# LPC18xx register map
File version: 18
Registers are 32-bit, read-write, reset 0x0 unless marked. A register's access mark holds for its fields unless they carry their own. Offsets are from the block's base; [hi:lo] are bit positions; {n}, {i} and the like mark numbered series; 'fields as' and 'values as' point back to an identical list.

## USB0 (part 1 of 2) — Product name title=UM10430 Chapter title=LPC18xx USB0 Host/Device/OTG controller Modification date=1/19/2011 Major revision=0 Minor revision=7
Base 0x40006000
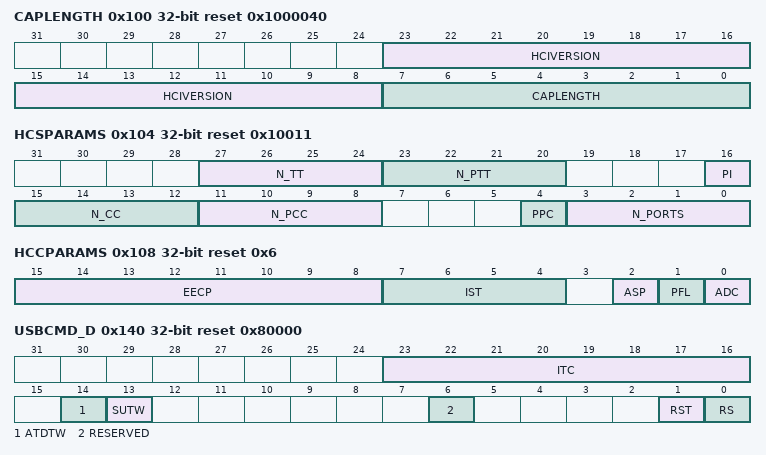
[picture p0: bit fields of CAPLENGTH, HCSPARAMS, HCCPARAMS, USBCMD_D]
0x100 CAPLENGTH ro reset 0x1000040 — Capability register length
  [23:8] HCIVERSION — BCD encoding of the EHCI revision number supported by this host controller.
  [7:0] CAPLENGTH — Indicates offset to add to the register base address at the beginning of the Operational Register
0x104 HCSPARAMS ro reset 0x10011 — Host controller structural parameters
  [27:24] N_TT — Number of Transaction Translators. This field indicates the number of embedded transaction translators associated with the USB2.0 host controller.
  [23:20] N_PTT — Number of Ports per Transaction Translator. This field indicates the number of ports assigned to each transaction translator within the USB2.0 host controller.
  [16] PI — Port indicators. This bit indicates whether the ports support port indicator control.
  [15:12] N_CC — Number of Companion Controller. This field indicates the number of companion controllers associated with this USB2.0 host controller.
  [11:8] N_PCC — Number of Ports per Companion Controller. This field indicates the number of ports supported per internal Companion Controller.
  [4] PPC — Port Power Control. This field indicates whether the host controller implementation includes port power control.
  [3:0] N_PORTS — Number of downstream ports. This field specifies the number of physical downstream ports implemented on this host controller.
0x108 HCCPARAMS ro reset 0x6 — Host controller capability parameters
  [15:8] EECP — EHCI Extended Capabilities Pointer. This optional field indicates the existence of a capabilities list.
  [7:4] IST — Isochronous Scheduling Threshold. This field indicates, relative to the current position of the executing host controller, where software can reliably update the isochronous schedule.
  [2] ASP — Asynchronous Schedule Park Capability. If this bit is set to a one, then the host controller supports the park feature for high-speed queue heads in the Asynchronous Schedule.The feature can be disabled or enabled and set to a specific level by using the Asynchronous Schedule Park Mode Enable and Asynchronous Schedule Park Mode Count fields in the USBCMD register.
  [1] PFL — Programmable Frame List Flag. If set to one, then the system software can specify and use a smaller frame list and configure the host controller via the USBCMD register Frame List Size field. The frame list must always be aligned on a 4K-boundary. This requirement ensures that the frame list is always physically contiguous.
  [0] ADC — 64-bit Addressing Capability. If zero, no 64-bit addressing capability is supported.
0x120 DCIVERSION ro reset 0x1 — Device interface version number
  [15:0] DCIVERSION — The device controller interface conforms to the two-byte BCD encoding of the interface version number contained in this register.
0x140 USBCMD_D reset 0x80000 — USB command (device mode)
  [23:16] ITC — Interrupt threshold control. The system software uses this field to set the maximum rate at which the host/device controller will issue interrupts. ITC contains the maximum interrupt interval measured in micro-frames. Valid values are shown below. All other values are reserved. 0x0 = Immediate (no threshold) 0x1 = 1 micro frame. 0x2 = 2 micro frames. 0x8 = 8 micro frames. 0x10 = 16 micro frames. 0x20 = 32 micro frames. 0x40 = 64 micro frames.
  [14] ATDTW — Add dTD trip wire This bit is used as a semaphore to ensure the to proper addition of a new dTD to an active (primed) endpoint's linked list. This bit is set and cleared by software during the process of adding a new dTD. See also Section 18.10. This bit shall also be cleared by hardware when its state machine is hazard region for which adding a dTD to a primed endpoint may go unrecognized.
  [13] SUTW — Setup trip wire During handling a setup packet, this bit is used as a semaphore to ensure that the setup data payload of 8 bytes is extracted from a QH by the DCD without being corrupted. If the setup lockout mode is off (see USBMODE register) then there exists a hazard when new setup data arrives while the DCD is copying the setup data payload from the QH for a previous setup packet. This bit is set and cleared by software and will be cleared by hardware when a hazard exists. (See Section 18.10).
  [6] RESERVED — Not used in device mode. Writing a one to this bit when the device mode is selected, will have undefined results.
  [1] RST — Controller reset. Software uses this bit to reset the controller. This bit is set to zero by the Host/Device Controller when the reset process is complete. Software cannot terminate the reset process early by writing a zero to this register.
    0=RESETCOMPLETE (Set to 0 by hardware when the reset process is complete.); 1=RESET (When software writes a one to this bit, the Device Controller resets its internal pipelines, timers, counters, state machines etc. to their initial values. Writing a one to this bit when the device is in the attached state is not recommended, since the effect on an attached host is undefined. In order to ensure that the device is not in an attached state before initiating a device controller reset, all primed endpoints should be flushed and the USBCMD Run/Stop bit should be set to 0.)
  [0] RS — Run/Stop
    0=DETACH (Writing a 0 to this bit will cause a detach event.); 1=ATTACH (Writing a one to this bit will cause the device controller to enable a pull-up on USB_DP and initiate an attach event. This control bit is not directly connected to the pull-up enable, as the pull-up will become disabled upon transitioning into high-speed mode. Software should use this bit to prevent an attach event before the device controller has been properly initialized.)
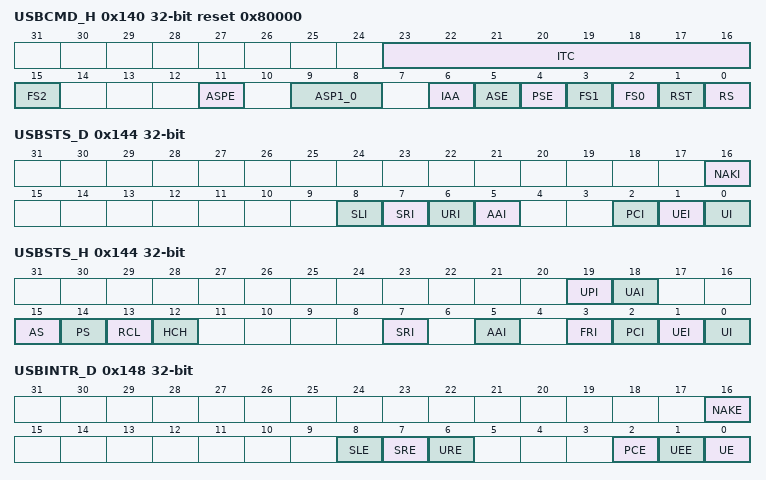
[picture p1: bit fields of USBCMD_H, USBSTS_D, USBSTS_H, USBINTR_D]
0x140 USBCMD_H reset 0x80000 (alternate view of USBCMD_D) — USB command (host mode)
  [23:16] ITC — Interrupt threshold control. The system software uses this field to set the maximum rate at which the host/device controller will issue interrupts. ITC contains the maximum interrupt interval measured in micro-frames. Valid values are shown below. All other values are reserved. 0x0 = Immediate (no threshold) 0x1 = 1 micro frame. 0x2 = 2 micro frames. 0x8 = 8 micro frames. 0x10 = 16 micro frames. 0x20 = 32 micro frames. 0x40 = 64 micro frames.
  [15] FS2 — Bit 2 of the Frame List Size bits. See Table 220.
  [11] ASPE — Asynchronous Schedule Park Mode Enable
    0=PARK_MODE_IS_DISABLE (Park mode is disabled.); 1=PARK_MODE_IS_ENABLED
  [9:8] ASP1_0 — Asynchronous schedule park mode Contains a count of the number of successive transactions the host controller is allowed to execute from a high-speed queue head on the Asynchronous schedule before continuing traversal of the Asynchronous schedule. Valid values are 0x1 to 0x3. Software must not write 00 to this bit when Park Mode Enable is one as this will result in undefined behavior.
  [6] IAA — This bit is used as a doorbell by software to tell the host controller to issue an interrupt the next time it advances asynchronous schedule.
    0=THE_HOST_CONTROLLER_ (The host controller sets this bit to zero after it has set the Interrupt on Sync Advance status bit in the USBSTS register to one.); 1=SOFTWARE_MUST_WRITE_ (Software must write a 1 to this bit to ring the doorbell. When the host controller has evicted all appropriate cached schedule states, it sets the Interrupt on Async Advance status bit in the USBSTS register. If the Interrupt on Sync Advance Enable bit in the USBINTR register is one, then the host controller will assert an interrupt at the next interrupt threshold. Software should not write a one to this bit when the asynchronous schedule is inactive. Doing so will yield undefined results.)
  [5] ASE — This bit controls whether the host controller skips processing the asynchronous schedule.
    0=DO_NOT_PROCESS_THE_A (Do not process the asynchronous schedule.); 1=USE_THE_ASYNCLISTADD (Use the ASYNCLISTADDR to access the asynchronous schedule.)
  [4] PSE — This bit controls whether the host controller skips processing the periodic schedule.
    0=DO_NOT_PROCESS_THE_P (Do not process the periodic schedule.); 1=USE_THE_PERIODICLIST (Use the PERIODICLISTBASE register to access the periodic schedule.)
  [3] FS1 — Bit 1 of the Frame List Size bits. See Table 220.
  [2] FS0 — Bit 0 of the Frame List Size bits. See Table 220. This field specifies the size of the frame list that controls which bits in the Frame Index Register should be used for the Frame List Current index. Note that this field is made up from USBCMD bits 15, 3, and 2.
  [1] RST — Controller reset. Software uses this bit to reset the controller. This bit is set to zero by the Host/Device Controller when the reset process is complete. Software cannot terminate the reset process early by writing a zero to this register.
    0=RESETCOMPLETE (This bit is set to zero by hardware when the reset process is complete.); 1=RESET (When software writes a one to this bit, the Host Controller resets its internal pipelines, timers, counters, state machines etc. to their initial value. Any transaction currently in progress on USB is immediately terminated. A USB reset is not driven on downstream ports. Software should not set this bit to a one when the HCHalted bit in the USBSTS register is a zero. Attempting to reset an actively running host controller will result in undefined behavior.)
  [0] RS — Run/Stop
    0=HALT (When this bit is set to 0, the Host Controller completes the current transaction on the USB and then halts. The HC Halted bit in the status register indicates when the Host Controller has finished the transaction and has entered the stopped state. Software should not write a one to this field unless the host controller is in the Halted state (i.e. HCHalted in the USBSTS register is a one).); 1=PROCEED (When set to a 1, the Host Controller proceeds with the execution of the schedule. The Host Controller continues execution as long as this bit is set to a one.)
0x144 USBSTS_D — USB status (device mode)
  [16] NAKI — NAK interrupt bit
    0=ST (This bit is automatically cleared by hardware when the all the enabled TX/RX Endpoint NAK bits are cleared.); 1=CLEAR (It is set by hardware when for a particular endpoint both the TX/RX Endpoint NAK bit and the corresponding TX/RX Endpoint NAK Enable bit are set.)
  [8] SLI — DCSuspend
    0=ST (The device controller clears the bit upon exiting from a suspend state. This bit is cleared by software writing a one to it.); 1=CLEAR (When a device controller enters a suspend state from an active state, this bit will be set to a one.)
  [7] SRI — SOF received
    0=ST (This bit is cleared by software writing a one to it.); 1=CLEAR (When the device controller detects a Start Of (micro) Frame, this bit will be set to a one. When a SOF is extremely late, the device controller will automatically set this bit to indicate that an SOF was expected. Therefore, this bit will be set roughly every 1 ms in device FS mode and every 125 ms in HS mode and will be synchronized to the actual SOF that is received. Since the device controller is initialized to FS before connect, this bit will be set at an interval of 1ms during the prelude to connect and chirp.)
  [6] URI — USB reset received
    0=ST (This bit is cleared by software writing a one to it.); 1=CLEAR (When the device controller detects a USB Reset and enters the default state, this bit will be set to a one.)
  [5] AAI — Not used in Device mode.
  [2] PCI — Port change detect.
    0=ST (This bit is cleared by software writing a one to it.); 1=CLEAR (The Device Controller sets this bit to a one when the port controller enters the full or high-speed operational state. When the port controller exits the full or high-speed operation states due to Reset or Suspend events, the notification mechanisms are the USB Reset Received bit (URI) and the DCSuspend bits (SLI) respectively.)
  [1] UEI — USB error interrupt
    0=ST (This bit is cleared by software writing a one to it.); 1=CLEAR (When completion of a USB transaction results in an error condition, this bit is set by the Host/Device Controller. This bit is set along with the USBINT bit, if the TD on which the error interrupt occurred also had its interrupt on complete (IOC) bit set. The device controller detects resume signaling only (see Section 18.10.11.6).)
  [0] UI — USB interrupt
    0=ST (This bit is cleared by software writing a one to it.); 1=CLEAR (This bit is set by the Host/Device Controller when the cause of an interrupt is a completion of a USB transaction where the Transfer Descriptor (TD) has an interrupt on complete (IOC) bit set. This bit is also set by the Host/Device Controller when a short packet is detected. A short packet is when the actual number of bytes received was less than the expected number of bytes.)
0x144 USBSTS_H (alternate view of USBSTS_D) — USB status (host mode)
  [19] UPI — USB host periodic interrupt (USBHSTPERINT)
    0=ST (This bit is cleared by software writing a one to it.); 1=CLEAR (This bit is set by the Host Controller when the cause of an interrupt is a completion of a USB transaction where the Transfer Descriptor (TD) has an interrupt on complete (IOC) bit set and the TD was from the periodic schedule. This bit is also set by the Host Controller when a short packet is detected and the packet is on the periodic schedule. A short packet is when the actual number of bytes received was less than the expected number of bytes.)
  [18] UAI — USB host asynchronous interrupt (USBHSTASYNCINT)
    0=ST (This bit is cleared by software writing a one to it.); 1=CLEAR (This bit is set by the Host Controller when the cause of an interrupt is a completion of a USB transaction where the Transfer Descriptor (TD) has an interrupt on complete (IOC) bit set and the TD was from the asynchronous schedule. This bit is also set by the Host when a short packet is detected and the packet is on the asynchronous schedule. A short packet is when the actual number of bytes received was less than the expected number of bytes.)
  [15] AS — Asynchronous schedule status This bit reports the current real status of the Asynchronous Schedule. The Host Controller is not required to immediately disable or enable the Asynchronous Schedule when software transitions the Asynchronous Schedule Enable bit in the USBCMD register. When this bit and the Asynchronous Schedule Enable bit are the same value, the Asynchronous Schedule is either enabled (if both are 1) or disabled (if both are 0).
    0=DISABLED (Asynchronous schedule status is disabled.); 1=DISABLED (Asynchronous schedule status is enabled.)
  [14] PS — Periodic schedule status This bit reports the current real status of the Periodic Schedule. The Host Controller is not required to immediately disable or enable the Periodic Schedule when software transitions the Periodic Schedule Enable bit in the USBCMD register. When this bit and the Periodic Schedule Enable bit are the same value, the Periodic Schedule is either enabled (if both are 1) or disabled (if both are 0).
    0=DISABLED (The periodic schedule status is disabled.); 1=DISABLED (The periodic schedule status is enabled.)
  [13] RCL — Reclamation
    0=NO_EMPTY_ASYNCHRONOU (No empty asynchronous schedule detected.); 1=EMPTY_ASYNCHRONOU (An empty asynchronous schedule is detected. Set by the host controller.)
  [12] HCH — HCHalted
    0=RS (The RS bit in USBCMD is set to zero. Set by the host controller.); 1=HALT (The Host Controller sets this bit to one after it has stopped executing because of the Run/Stop bit being set to 0, either by software or by the Host Controller hardware (e.g. because of an internal error).)
  [7] SRI — SOF received
    0=ST (This bit is cleared by software writing a one to it.); 1=CLEAR (In host mode, this bit will be set every 125 ms and can be used by host controller driver as a time base.)
  [5] AAI — Interrupt on async advance
    0=ST (This bit is cleared by software writing a one to it.); 1=CLEAR (System software can force the host controller to issue an interrupt the next time the host controller advances the asynchronous schedule by writing a one to the Interrupt on Async Advance Doorbell bit in the USBCMD register. This status bit indicates the assertion of that interrupt source.)
  [3] FRI — Frame list roll-over
    0=ST (This bit is cleared by software writing a one to it.); 1=CLEAR (The Host Controller sets this bit to a one when the Frame List Index rolls over from its maximum value to zero. The exact value at which the rollover occurs depends on the frame list size. For example, if the frame list size (as programmed in the Frame List Size field of the USBCMD register) is 1024, the Frame Index Register rolls over every time FRINDEX bit 13 toggles. Similarly, if the size is 512, the Host Controller sets this bit to a one every time FRINDEX bit 12 toggles (see Section 18.6.6).)
  [2] PCI — Port change detect.
    0=ST (This bit is cleared by software writing a one to it.); 1=CLEAR (The Host Controller sets this bit to a one when on any port a Connect Status occurs, a Port Enable/Disable Change occurs, or the Force Port Resume bit is set as the result of a J-K transition on the suspended port.)
  [1] UEI — USB error interrupt (USBERRINT)
    0=ST (This bit is cleared by software writing a one to it.); 1=CLEAR (When completion of a USB transaction results in an error condition, this bit is set by the Host/Device Controller. This bit is set along with the USBINT bit, if the TD on which the error interrupt occurred also had its interrupt on complete (IOC) bit set.)
  [0] UI — USB interrupt (USBINT)
    values as USBSTS_D.UI
0x148 USBINTR_D — USB interrupt enable (device mode)
  [16] NAKE — NAK interrupt enable This bit is set by software if it wants to enable the hardware interrupt for the NAK Interrupt bit. If both this bit and the corresponding NAK Interrupt bit are set, a hardware interrupt is generated.
  [8] SLE — Sleep enable When this bit is a one, and the DCSuspend bit in the USBSTS register transitions, the device controller will issue an interrupt. The interrupt is acknowledged by software writing a one to the DCSuspend bit.
  [7] SRE — SOF received enable When this bit is a one, and the SOF Received bit in the USBSTS register is a one, the device controller will issue an interrupt. The interrupt is acknowledged by software clearing the SOF Received bit.
  [6] URE — USB reset enable When this bit is a one, and the USB Reset Received bit in the USBSTS register is a one, the device controller will issue an interrupt. The interrupt is acknowledged by software clearing the USB Reset Received bit.
  [2] PCE — Port change detect enable When this bit is a one, and the Port Change Detect bit in the USBSTS register is a one, the host/device controller will issue an interrupt. The interrupt is acknowledged by software clearing the Port Change Detect bit in USBSTS.
  [1] UEE — USB error interrupt enable When this bit is a one, and the USBERRINT bit in the USBSTS register is a one, the host/device controller will issue an interrupt at the next interrupt threshold. The interrupt is acknowledged by software clearing the USBERRINT bit in the USBSTS register.
  [0] UE — USB interrupt enable When this bit is one, and the USBINT bit in the USBSTS register is one, the host/device controller will issue an interrupt at the next interrupt threshold. The interrupt is acknowledged by software clearing the USBINT bit in USBSTS.
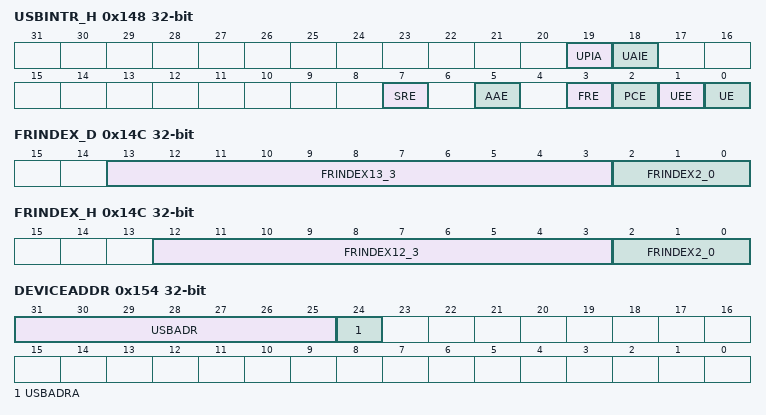
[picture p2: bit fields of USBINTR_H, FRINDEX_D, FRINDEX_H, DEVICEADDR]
0x148 USBINTR_H (alternate view of USBINTR_D) — USB interrupt enable (host mode)
  [19] UPIA — USB host periodic interrupt enable When this bit is a one, and the USBHSTPERINT bit in the USBSTS register is a one, the host controller will issue an interrupt at the next interrupt threshold. The interrupt is acknowledged by software clearing the USBHSTPERINT bit.
  [18] UAIE — USB host asynchronous interrupt enable When this bit is a one, and the USBHSTASYNCINT bit in the USBSTS register is a one, the host controller will issue an interrupt at the next interrupt threshold. The interrupt is acknowledged by software clearing the USBHSTASYNCINT bit.
  [7] SRE — If this bit is one and the SRI bit in the USBSTS register is one, the host controller will issue an interrupt. In host mode, the SRI bit will be set every 125 ms and can be used by the host controller as a time base. The interrupt is acknowledged by software clearing the SRI bit in the USBSTS register.
  [5] AAE — Interrupt on asynchronous advance enable When this bit is a one, and the Interrupt on Async Advance bit in the USBSTS register is a one, the host controller will issue an interrupt at the next interrupt threshold. The interrupt is acknowledged by software clearing the Interrupt on Async Advance bit.
  [3] FRE — Frame list rollover enable When this bit is a one, and the Frame List Rollover bit in the USBSTS register is a one, the host controller will issue an interrupt. The interrupt is acknowledged by software clearing the Frame List Rollover bit.
  [2] PCE — Port change detect enable When this bit is a one, and the Port Change Detect bit in the USBSTS register is a one, the host/device controller will issue an interrupt. The interrupt is acknowledged by software clearing the Port Change Detect bit in USBSTS.
  [1] UEE — USB error interrupt enable When this bit is a one, and the USBERRINT bit in the USBSTS register is a one, the host/device controller will issue an interrupt at the next interrupt threshold. The interrupt is acknowledged by software clearing the USBERRINT bit in the USBSTS register.
  [0] UE — USB interrupt enable When this bit is one, and the USBINT bit in the USBSTS register is one, the host/device controller will issue an interrupt at the next interrupt threshold. The interrupt is acknowledged by software clearing the USBINT bit in USBSTS.
0x14C FRINDEX_D — USB frame index (device mode)
  [13:3] FRINDEX13_3 — Current frame number of the last frame transmitted
  [2:0] FRINDEX2_0 — Current micro frame number
0x14C FRINDEX_H (alternate view of FRINDEX_D) — USB frame index (host mode)
  [12:3] FRINDEX12_3 — Frame list current index.
  [2:0] FRINDEX2_0 — Current micro frame number
0x154 DEVICEADDR — USB device address (device mode)
  [31:25] USBADR — USB device address
  [24] USBADRA — Device address advance
    0=INSTANTANEOUS (Any write to USBADR are instantaneous.); 1=DELAYED (When the user writes a one to this bit at the same time or before USBADR is written, the write to USBADR fields is staged and held in a hidden register. After an IN occurs on endpoint 0 and is acknowledged, USBADR will be loaded from the holding register. Hardware will automatically clear this bit on the following conditions: IN is ACKed to endpoint 0. USBADR is updated from the staging register. OUT/SETUP occurs on endpoint 0. USBADR is not updated. Device reset occurs. USBADR is set to 0. After the status phase of the SET_ADDRESS descriptor, the DCD has 2 ms to program the USBADR field. This mechanism will ensure this specification is met when the DCD can not write the device address within 2 ms from the SET_ADDRESS status phase. If the DCD writes the USBADR with USBADRA=1 after the SET_ADDRESS data phase (before the prime of the status phase), the USBADR will be programmed instantly at the correct time and meet the 2 ms USB requirement.)
0x154 PERIODICLISTBASE (alternate view of DEVICEADDR) — Frame list base address (host mode)
  [31:12] PERBASE31_12 — Base Address (Low) These bits correspond to the memory address signals 31:12.
0x158 ENDPOINTLISTADDR — Address of endpoint list in memory
  [31:11] EPBASE31_11 — Endpoint list pointer (low) These bits correspond to memory address signals 31:11, respectively. This field will reference a list of up to 4 Queue Heads (QH). (i.e. one queue head per endpoint and direction.)
0x158 ASYNCLISTADDR (alternate view of ENDPOINTLISTADDR) — Address of endpoint list in memory
  [31:5] ASYBASE31_5 — Link pointer (Low) LPL These bits correspond to memory address signals 31:5, respectively. This field may only reference a Queue Head (OH).
0x15C TTCTRL — Asynchronous buffer status for embedded TT (host mode)
  [30:24] TTHA — Hub address when FS or LS device are connected directly.
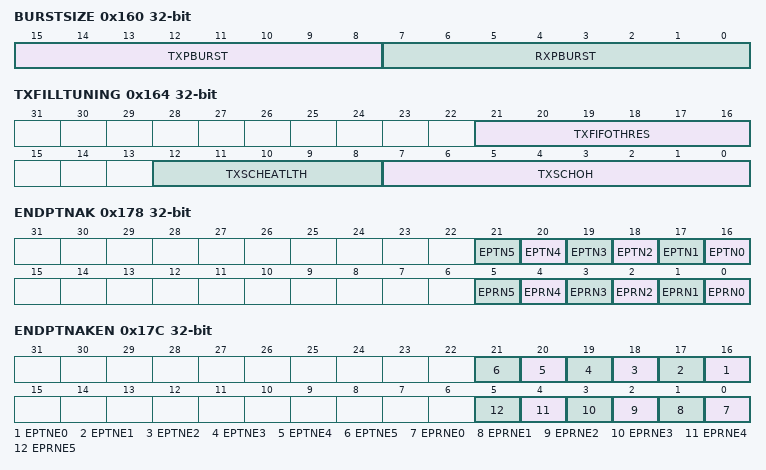
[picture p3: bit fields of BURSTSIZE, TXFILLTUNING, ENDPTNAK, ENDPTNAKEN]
0x160 BURSTSIZE — Programmable burst size
  [15:8] TXPBURST — Programmable TX burst length This register represents the maximum length of a burst in 32-bit words while moving data from system memory to the USB bus.
  [7:0] RXPBURST — Programmable RX burst length This register represents the maximum length of a burst in 32-bit words while moving data from the USB bus to system memory.
0x164 TXFILLTUNING — Host transmit pre-buffer packet tuning (host mode)
  [21:16] TXFIFOTHRES — Scheduler overhead This register adds an additional fixed offset to the schedule time estimator described above as Tff. As an approximation, the value chosen for this register should limit the number of back-off events captured in the TXSCHHEALTH to less than 10 per second in a highly utilized bus. Choosing a value that is too high for this register is not desired as it can needlessly reduce USB utilization. The time unit represented in this register is 1.267 ms when a device is connected in High-Speed Mode for OTG and SPH. The time unit represented in this register is 6.333 ms when a device is connected in Low/Full Speed Mode for OTG and SPH.
  [12:8] TXSCHEATLTH — Scheduler health counter This register increments when the host controller fails to fill the TX latency FIFO to the level programmed by TXFIFOTHRES before running out of time to send the packet before the next Start-Of-Frame . This health counter measures the number of times this occurs to provide feedback to selecting a proper TXSCHOH. Writing to this register will clear the counter. The maximum value is 31.
  [7:0] TXSCHOH — FIFO burst threshold This register controls the number of data bursts that are posted to the TX latency FIFO in host mode before the packet begins on to the bus. The minimum value is 2 and this value should be a low as possible to maximize USB performance. A higher value can be used in systems with unpredictable latency and/or insufficient bandwidth where the FIFO may underrun because the data transferred from the latency FIFO to USB occurs before it can be replenished from system memory. This value is ignored if the Stream Disable bit in USBMODE register is set.
0x174 BINTERVAL — Length of virtual frame
  [3:0] BINT — bInterval value (see Section 18.7.7)
0x178 ENDPTNAK — Endpoint NAK (device mode)
  [n+16] EPTN{n} (n=0..5) — Tx endpoint NAK Each TX endpoint has one bit in this field. The bit is set when the device sends a NAK handshake on a received IN token for the corresponding endpoint. Bit 3 corresponds to endpoint 3. ... Bit 1 corresponds to endpoint 1. Bit 0 corresponds to endpoint 0.
  [n] EPRN{n} (n=0..5) — Rx endpoint NAK Each RX endpoint has one bit in this field. The bit is set when the device sends a NAK handshake on a received OUT or PING token for the corresponding endpoint. Bit 5 corresponds to endpoint 5. ... Bit 1 corresponds to endpoint 1. Bit 0 corresponds to endpoint 0.
0x17C ENDPTNAKEN — Endpoint NAK Enable (device mode)
  [n+16] EPTNE{n} (n=0..5) — Tx endpoint NAK Each bit enables the corresponding TX NAK bit. If this bit is set and the corresponding TX endpoint NAK bit is set, the NAK interrupt bit is set. Bit 5 corresponds to endpoint 5. ... Bit 1 corresponds to endpoint 1. Bit 0 corresponds to endpoint 0.
  [n] EPRNE{n} (n=0..5) — Rx endpoint NAK enable Each bit enables the corresponding RX NAK bit. If this bit is set and the corresponding RX endpoint NAK bit is set, the NAK interrupt bit is set. Bit 5 corresponds to endpoint 5. ... Bit 1 corresponds to endpoint 1. Bit 0 corresponds to endpoint 0.
